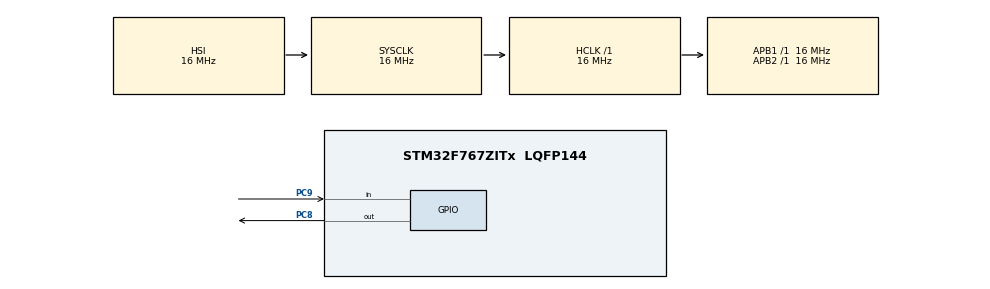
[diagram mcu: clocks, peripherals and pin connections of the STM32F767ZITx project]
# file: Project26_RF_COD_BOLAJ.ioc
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Mcu.Family=STM32F7
Mcu.Name=STM32F767ZITx
Mcu.Package=LQFP144
NVIC.PriorityGroup=NVIC_PRIORITYGROUP_4
PC8.Signal=GPIO_Output
PC9.Signal=GPIO_Input
PH0/OSC_IN.Mode=HSE-External-Oscillator
PH0/OSC_IN.Signal=RCC_OSC_IN
PH1/OSC_OUT.Mode=HSE-External-Oscillator
PH1/OSC_OUT.Signal=RCC_OSC_OUT
ProjectManager.HeapSize=0x200
ProjectManager.StackSize=0x400
ProjectManager.TargetToolchain=EWARM V8
RCC.48MHZClocksFreq_Value=24000000
RCC.AHBFreq_Value=16000000
RCC.APB1Freq_Value=16000000
RCC.APB1TimFreq_Value=16000000
RCC.APB2Freq_Value=16000000
RCC.APB2TimFreq_Value=16000000
RCC.CortexFreq_Value=16000000
RCC.HCLKFreq_Value=16000000
RCC.HSE_VALUE=16000000
RCC.HSI_VALUE=16000000
RCC.LSE_VALUE=32768
RCC.PLLMUL=RCC_PLL_MUL9
RCC.PRESCALERUSB=RCC_USBCLKSOURCE_PLL_DIV1_5
RCC.SYSCLKFreq_VALUE=16000000
RCC.SYSCLKSourceVirtual=RCC_SYSCLKSOURCE_PLLCLK
RCC.USBFreq_Value=96000000
RCC.VCOOutputFreq_Value=192000000
board=NUCLEO-F767ZI

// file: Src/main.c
/* USER CODE BEGIN Header */
/**
  ******************************************************************************
  * @file           : main.c
  * @brief          : Main program body
  ******************************************************************************
  * @attention
  *
  * <h2><center>&copy; Copyright (c) 2021 STMicroelectronics.
  * All rights reserved.</center></h2>
  *
  * This software component is licensed by ST under BSD 3-Clause license,
  * the "License"; You may not use this file except in compliance with the
  * License. You may obtain a copy of the License at:
  *                        opensource.org/licenses/BSD-3-Clause
  *
  ******************************************************************************
  */
/* USER CODE END Header */

#include "main.h"
#include "stm32xxxx_rf.h"

/* USER CODE BEGIN PV */
uint16_t step = 0;
 uint32_t msg[] = {1, 0, 1, 0, 0, 1, 1, 1};
 uint8_t msg2[8];
 RF_HandleTypeDef rf;

RF_TxMsgTypeDef TxM;
RF_RxMsgTypeDef RxM;
/* USER CODE END PV */

void SystemClock_Config(void);
static void MX_GPIO_Init(void);

int main(void)
{

  /* MCU Configuration--------------------------------------------------------*/

  /* Reset of all peripherals, Initializes the Flash interface and the Systick. */
  HAL_Init();

  /* Configure the system clock */
  SystemClock_Config();

  /* Initialize all configured peripherals */
  MX_GPIO_Init();
  /* USER CODE BEGIN 2 */
 TxM.ID = 0x244;

  for(int i = 0; i < 8; ++i)
    TxM.Data[i] = msg[i];

  rf.pTxMsg = &TxM;
  rf.pRxMsg = &RxM;
  /* USER CODE END 2 */

  /* Infinite loop */
  while (1)
  {

    RF_Transmit(&rf, HAL_MAX_DELAY);
    RF_Receive (&rf, HAL_MAX_DELAY);

  }
}

void SystemClock_Config(void)
{
  RCC_OscInitTypeDef RCC_OscInitStruct = {0};
  RCC_ClkInitTypeDef RCC_ClkInitStruct = {0};

  /** Configure the main internal regulator output voltage
  */
  __HAL_RCC_PWR_CLK_ENABLE();
  __HAL_PWR_VOLTAGESCALING_CONFIG(PWR_REGULATOR_VOLTAGE_SCALE3);
  /** Initializes the CPU, AHB and APB busses clocks
  */
  RCC_OscInitStruct.OscillatorType = RCC_OSCILLATORTYPE_HSI;
  RCC_OscInitStruct.HSIState = RCC_HSI_ON;
  RCC_OscInitStruct.HSICalibrationValue = RCC_HSICALIBRATION_DEFAULT;
  RCC_OscInitStruct.PLL.PLLState = RCC_PLL_NONE;
  if (HAL_RCC_OscConfig(&RCC_OscInitStruct) != HAL_OK)
  {
    Error_Handler();
  }
  /** Initializes the CPU, AHB and APB busses clocks
  */
  RCC_ClkInitStruct.ClockType = RCC_CLOCKTYPE_HCLK|RCC_CLOCKTYPE_SYSCLK
                              |RCC_CLOCKTYPE_PCLK1|RCC_CLOCKTYPE_PCLK2;
  RCC_ClkInitStruct.SYSCLKSource = RCC_SYSCLKSOURCE_HSI;
  RCC_ClkInitStruct.AHBCLKDivider = RCC_SYSCLK_DIV1;
  RCC_ClkInitStruct.APB1CLKDivider = RCC_HCLK_DIV1;
  RCC_ClkInitStruct.APB2CLKDivider = RCC_HCLK_DIV1;

  if (HAL_RCC_ClockConfig(&RCC_ClkInitStruct, FLASH_LATENCY_0) != HAL_OK)
  {
    Error_Handler();
  }
}

static void MX_GPIO_Init(void)
{
  GPIO_InitTypeDef GPIO_InitStruct = {0};

  /* GPIO Ports Clock Enable */
  __HAL_RCC_GPIOH_CLK_ENABLE();
  __HAL_RCC_GPIOC_CLK_ENABLE();

  /*Configure GPIO pin Output Level */
  HAL_GPIO_WritePin(GPIOC, GPIO_PIN_8, GPIO_PIN_RESET);

  /*Configure GPIO pin : PC8 */
  GPIO_InitStruct.Pin = GPIO_PIN_8;
  GPIO_InitStruct.Mode = GPIO_MODE_OUTPUT_PP;
  GPIO_InitStruct.Pull = GPIO_NOPULL;
  GPIO_InitStruct.Speed = GPIO_SPEED_FREQ_LOW;
  HAL_GPIO_Init(GPIOC, &GPIO_InitStruct);

  /*Configure GPIO pin : PC9 */
  GPIO_InitStruct.Pin = GPIO_PIN_9;
  GPIO_InitStruct.Mode = GPIO_MODE_INPUT;
  GPIO_InitStruct.Pull = GPIO_NOPULL;
  HAL_GPIO_Init(GPIOC, &GPIO_InitStruct);

}

void Error_Handler(void)
{
}

/************************ (C) COPYRIGHT STMicroelectronics *****END OF FILE****/
